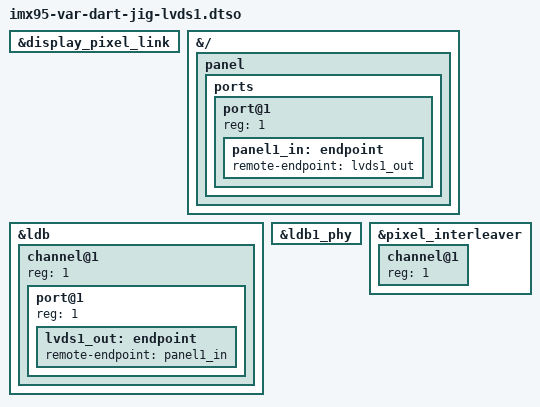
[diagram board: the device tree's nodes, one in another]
// SPDX-License-Identifier: (GPL-2.0+ OR MIT)
/*
 * Copyright 2023 NXP
 * Copyright 2024 Variscite Ltd.
 */

/dts-v1/;
/plugin/;

#include <dt-bindings/gpio/gpio.h>
#include <dt-bindings/clock/fsl,imx95-clock.h>

&display_pixel_link {
    status = "okay";
};

&{/} {
    panel {
        ports {
            #address-cells = <1>;
            #size-cells = <0>;

            port@1 {
                reg = <1>;

                panel1_in: endpoint {
                    remote-endpoint = <&lvds1_out>;
                };
            };
        };
    };
};

&ldb {
	#address-cells = <1>;
	#size-cells = <0>;

	channel@1 {
		#address-cells = <1>;
		#size-cells = <0>;
		status = "okay";
		reg = <1>;

		port@1 {
			reg = <1>;

			lvds1_out: endpoint {
				remote-endpoint = <&panel1_in>;
			};
		};
	};
};

&ldb1_phy {
    status = "okay";
};

&pixel_interleaver {
	#address-cells = <1>;
	#size-cells = <0>;
	status = "okay";

	channel@1 {
		reg = <1>;
		status = "okay";
	};
};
